VERSION ""

NS_ :

BS_:

BU_: sensors slave master

BO_ 5 SlaveConnectMaster: 1 slave
 SG_ Reset : 0|1@1+ (1,0) [0|1] "" Vector__XXX

BO_ 6 MasterConnectSlave: 1 master
 SG_ Connect_Slave : 0|1@1+ (1,0) [0|1] "" Vector__XXX

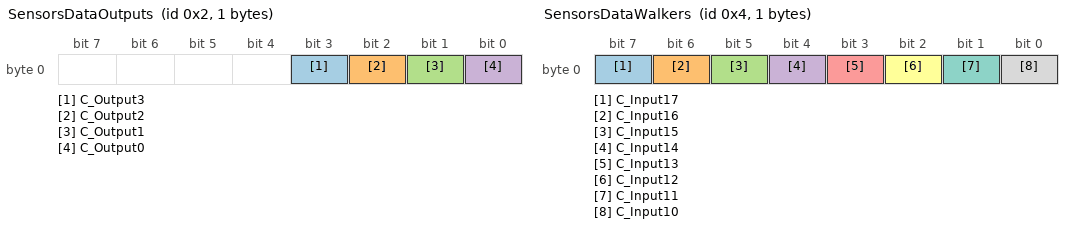
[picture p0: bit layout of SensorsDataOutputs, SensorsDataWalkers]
BO_ 2 SensorsDataOutputs: 1 sensors
 SG_ C_Output3 : 3|1@1+ (1,0) [0|1] "" Vector__XXX
 SG_ C_Output2 : 2|1@1+ (1,0) [0|1] "" Vector__XXX
 SG_ C_Output1 : 1|1@1+ (1,0) [0|1] "" Vector__XXX
 SG_ C_Output0 : 0|1@1+ (1,0) [0|1] "" Vector__XXX

BO_ 4 SensorsDataWalkers: 1 sensors
 SG_ C_Input17 : 7|1@1+ (1,0) [0|1] "" Vector__XXX
 SG_ C_Input16 : 6|1@1+ (1,0) [0|1] "" Vector__XXX
 SG_ C_Input15 : 5|1@1+ (1,0) [0|1] "" Vector__XXX
 SG_ C_Input14 : 4|1@1+ (1,0) [0|1] "" Vector__XXX
 SG_ C_Input13 : 3|1@1+ (1,0) [0|1] "" Vector__XXX
 SG_ C_Input12 : 2|1@1+ (1,0) [0|1] "" Vector__XXX
 SG_ C_Input11 : 1|1@1+ (1,0) [0|1] "" Vector__XXX
 SG_ C_Input10 : 0|1@1+ (1,0) [0|1] "" Vector__XXX

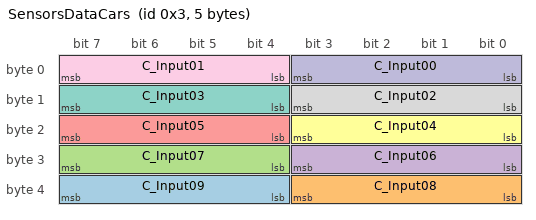
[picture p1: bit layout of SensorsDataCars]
BO_ 3 SensorsDataCars: 5 sensors
 SG_ C_Input09 : 36|4@1+ (1,0) [0|15] "" Vector__XXX
 SG_ C_Input08 : 32|4@1+ (1,0) [0|15] "" Vector__XXX
 SG_ C_Input07 : 28|4@1+ (1,0) [0|15] "" Vector__XXX
 SG_ C_Input06 : 24|4@1+ (1,0) [0|15] "" Vector__XXX
 SG_ C_Input05 : 20|4@1+ (1,0) [0|15] "" Vector__XXX
 SG_ C_Input04 : 16|4@1+ (1,0) [0|15] "" Vector__XXX
 SG_ C_Input03 : 12|4@1+ (1,0) [0|15] "" Vector__XXX
 SG_ C_Input02 : 8|4@1+ (1,0) [0|15] "" Vector__XXX
 SG_ C_Input01 : 4|4@1+ (1,0) [0|15] "" Vector__XXX
 SG_ C_Input00 : 0|4@1+ (1,0) [0|15] "" Vector__XXX

BO_ 1 RequestSensorsData: 1 master
 SG_ OK : 0|1@1+ (1,0) [0|1] "" Vector__XXX

BO_ 9 TrafficLightsControl: 7 slave
 SG_ output8_rightArrow : 49|1@1+ (1,0) [0|1] "" Vector__XXX
 SG_ output5_rightArrow : 48|1@1+ (1,0) [0|1] "" Vector__XXX
 SG_ output3_rightArrow : 47|1@1+ (1,0) [0|1] "" Vector__XXX
 SG_ output0_rightArrow : 46|1@1+ (1,0) [0|1] "" Vector__XXX
 SG_ output17_green : 45|1@1+ (1,0) [0|1] "" Vector__XXX
 SG_ output16_green : 43|1@1+ (1,0) [0|1] "" Vector__XXX
 SG_ output15_green : 41|1@1+ (1,0) [0|1] "" Vector__XXX
 SG_ output14_green : 39|1@1+ (1,0) [0|1] "" Vector__XXX
 SG_ output13_green : 37|1@1+ (1,0) [0|1] "" Vector__XXX
 SG_ output12_green : 35|1@1+ (1,0) [0|1] "" Vector__XXX
 SG_ output11_green : 33|1@1+ (1,0) [0|1] "" Vector__XXX
 SG_ output10_green : 31|1@1+ (1,0) [0|1] "" Vector__XXX
 SG_ output17_red : 44|1@1+ (1,0) [0|1] "" Vector__XXX
 SG_ output16_red : 42|1@1+ (1,0) [0|1] "" Vector__XXX
 SG_ output15_red : 40|1@1+ (1,0) [0|1] "" Vector__XXX
 SG_ output14_red : 38|1@1+ (1,0) [0|1] "" Vector__XXX
 SG_ output13_red : 36|1@1+ (1,0) [0|1] "" Vector__XXX
 SG_ output9_yellow : 29|1@1+ (1,0) [0|1] "" Vector__XXX
 SG_ output9_green : 27|1@1+ (1,0) [0|1] "" Vector__XXX
 SG_ output8_green : 24|1@1+ (1,0) [0|1] "" Vector__XXX
 SG_ output8_yellow : 26|1@1+ (1,0) [0|1] "" Vector__XXX
 SG_ output7_yellow : 23|1@1+ (1,0) [0|1] "" Vector__XXX
 SG_ output7_green : 21|1@1+ (1,0) [0|1] "" Vector__XXX
 SG_ output6_yellow : 20|1@1+ (1,0) [0|1] "" Vector__XXX
 SG_ output6_green : 18|1@1+ (1,0) [0|1] "" Vector__XXX
 SG_ output5_green : 15|1@1+ (1,0) [0|1] "" Vector__XXX
 SG_ output5_yellow : 17|1@1+ (1,0) [0|1] "" Vector__XXX
 SG_ output4_yellow : 14|1@1+ (1,0) [0|1] "" Vector__XXX
 SG_ output3_yellow : 11|1@1+ (1,0) [0|1] "" Vector__XXX
 SG_ output4_green : 12|1@1+ (1,0) [0|1] "" Vector__XXX
 SG_ output3_green : 9|1@1+ (1,0) [0|1] "" Vector__XXX
 SG_ output2_yellow : 8|1@1+ (1,0) [0|1] "" Vector__XXX
 SG_ output2_green : 6|1@1+ (1,0) [0|1] "" Vector__XXX
 SG_ output1_yellow : 5|1@1+ (1,0) [0|1] "" Vector__XXX
 SG_ output1_green : 3|1@1+ (1,0) [0|1] "" Vector__XXX
 SG_ output0_yellow : 2|1@1+ (1,0) [0|1] "" Vector__XXX
 SG_ output0_green : 0|1@1+ (1,0) [0|1] "" Vector__XXX
 SG_ output12_red : 34|1@1+ (1,0) [0|1] "" Vector__XXX
 SG_ output11_red : 32|1@1+ (1,0) [0|1] "" Vector__XXX
 SG_ output10_red : 30|1@1+ (1,0) [0|1] "" Vector__XXX
 SG_ output7_red : 22|1@1+ (1,0) [0|1] "" Vector__XXX
 SG_ output9_red : 28|1@1+ (1,0) [0|1] "" Vector__XXX
 SG_ output8_red : 25|1@1+ (1,0) [0|1] "" Vector__XXX
 SG_ output6_red : 19|1@1+ (1,0) [0|1] "" Vector__XXX
 SG_ output5_red : 16|1@1+ (1,0) [0|1] "" Vector__XXX
 SG_ output4_red : 13|1@1+ (1,0) [0|1] "" Vector__XXX
 SG_ output3_red : 10|1@1+ (1,0) [0|1] "" Vector__XXX
 SG_ output2_red : 7|1@1+ (1,0) [0|1] "" Vector__XXX
 SG_ output1_red : 4|1@1+ (1,0) [0|1] "" Vector__XXX
 SG_ output0_red : 1|1@1+ (1,0) [0|1] "" Vector__XXX

BO_ 77 CyclePhase: 8 master
 SG_ input21 : 21|1@1+ (1,0) [0|1] "" Vector__XXX
 SG_ input20 : 20|1@1+ (1,0) [0|1] "" Vector__XXX
 SG_ input19 : 19|1@1+ (1,0) [0|1] "" Vector__XXX
 SG_ input18 : 18|1@1+ (1,0) [0|1] "" Vector__XXX
 SG_ input9 : 17|1@1+ (1,0) [0|1] "" Vector__XXX
 SG_ input8 : 16|1@1+ (1,0) [0|1] "" Vector__XXX
 SG_ input7 : 15|1@1+ (1,0) [0|1] "" Vector__XXX
 SG_ input6 : 14|1@1+ (1,0) [0|1] "" Vector__XXX
 SG_ input5 : 13|1@1+ (1,0) [0|1] "" Vector__XXX
 SG_ input4 : 12|1@1+ (1,0) [0|1] "" Vector__XXX
 SG_ input3 : 11|1@1+ (1,0) [0|1] "" Vector__XXX
 SG_ input2 : 10|1@1+ (1,0) [0|1] "" Vector__XXX
 SG_ input17 : 9|1@1+ (1,0) [0|1] "" Vector__XXX
 SG_ input16 : 8|1@1+ (1,0) [0|1] "" Vector__XXX
 SG_ input15 : 7|1@1+ (1,0) [0|1] "" Vector__XXX
 SG_ input14 : 6|1@1+ (1,0) [0|1] "" Vector__XXX
 SG_ input13 : 5|1@1+ (1,0) [0|1] "" Vector__XXX
 SG_ input12 : 4|1@1+ (1,0) [0|1] "" Vector__XXX
 SG_ input11 : 3|1@1+ (1,0) [0|1] "" Vector__XXX
 SG_ input10 : 2|1@1+ (1,0) [0|1] "" Vector__XXX
 SG_ input1 : 1|1@1+ (1,0) [0|1] "" Vector__XXX
 SG_ time : 32|32@1- (1,0) [0|0] "" Vector__XXX
 SG_ input0 : 0|1@1+ (1,0) [0|1] "" Vector__XXX

EV_ T_faza4: 1 [0|0] "" 15 1 DUMMY_NODE_VECTOR3 Vector__XXX;

EV_ T_faza3: 1 [0|0] "" 15 2 DUMMY_NODE_VECTOR3 Vector__XXX;

EV_ T_faza2: 1 [0|0] "" 15 3 DUMMY_NODE_VECTOR3 Vector__XXX;

EV_ T_faza1: 1 [0|0] "" 15 4 DUMMY_NODE_VECTOR3 Vector__XXX;

EV_ Slave_On_Off: 0 [0|1] "" 1 5 DUMMY_NODE_VECTOR3 Vector__XXX;

EV_ TminP: 1 [0|0] "" 10 6 DUMMY_NODE_VECTOR3 Vector__XXX;

EV_ Master_On_Off: 0 [0|1] "" 1 7 DUMMY_NODE_VECTOR3 Vector__XXX;

EV_ Sensors_On_Off: 0 [0|1] "" 1 8 DUMMY_NODE_VECTOR3 Vector__XXX;

EV_ Tcycle: 1 [0|0] "" 60 9 DUMMY_NODE_VECTOR3 Vector__XXX;

EV_ Frequency17: 0 [0|32] "" 0 10 DUMMY_NODE_VECTOR3  sensors;

EV_ Frequency16: 0 [0|32] "" 0 11 DUMMY_NODE_VECTOR3  sensors;

EV_ Frequency15: 0 [0|32] "" 0 12 DUMMY_NODE_VECTOR3  sensors;

EV_ Frequency14: 0 [0|32] "" 0 13 DUMMY_NODE_VECTOR3  sensors;

EV_ Frequency13: 0 [0|32] "" 0 14 DUMMY_NODE_VECTOR3  sensors;

EV_ Frequency12: 0 [0|32] "" 0 15 DUMMY_NODE_VECTOR3  sensors;

EV_ Frequency11: 0 [0|32] "" 0 16 DUMMY_NODE_VECTOR3  sensors;

EV_ Frequency10: 0 [0|32] "" 0 17 DUMMY_NODE_VECTOR3  sensors;

EV_ Frequency9: 0 [0|32] "" 0 18 DUMMY_NODE_VECTOR3  sensors;

EV_ Frequency8: 0 [0|32] "" 0 19 DUMMY_NODE_VECTOR3  sensors;

EV_ Frequency7: 0 [0|32] "" 0 20 DUMMY_NODE_VECTOR3  sensors;

EV_ Frequency6: 0 [0|32] "" 0 21 DUMMY_NODE_VECTOR3  sensors;

EV_ Frequency5: 0 [0|32] "" 0 22 DUMMY_NODE_VECTOR3  sensors;

EV_ Frequency4: 0 [0|32] "" 0 23 DUMMY_NODE_VECTOR3  sensors;

EV_ Frequency3: 0 [0|32] "" 0 24 DUMMY_NODE_VECTOR3  sensors;

EV_ Frequency2: 0 [0|32] "" 0 25 DUMMY_NODE_VECTOR3  sensors;

EV_ Frequency1: 0 [0|32] "" 0 26 DUMMY_NODE_VECTOR3  sensors;

EV_ Frequency0: 0 [0|32] "" 0 27 DUMMY_NODE_VECTOR3  sensors;

EV_ Check_Input0: 0 [0|0] "" 1 28 DUMMY_NODE_VECTOR3  sensors;

EV_ Check_Input10: 0 [0|0] "" 0 29 DUMMY_NODE_VECTOR3  sensors;

EV_ Check_Input11: 0 [0|0] "" 0 30 DUMMY_NODE_VECTOR3  sensors;

EV_ Check_Input12: 0 [0|0] "" 0 31 DUMMY_NODE_VECTOR3  sensors;

EV_ Check_Input13: 0 [0|0] "" 0 32 DUMMY_NODE_VECTOR3  sensors;

EV_ Check_Input14: 0 [0|0] "" 0 33 DUMMY_NODE_VECTOR3  sensors;

EV_ Check_Input15: 0 [0|0] "" 0 34 DUMMY_NODE_VECTOR3  sensors;

EV_ Check_Input16: 0 [0|0] "" 0 35 DUMMY_NODE_VECTOR3  sensors;

EV_ Check_Input5: 0 [0|0] "" 1 36 DUMMY_NODE_VECTOR3  sensors;

EV_ Check_Input6: 0 [0|0] "" 1 37 DUMMY_NODE_VECTOR3  sensors;

EV_ Check_Input7: 0 [0|0] "" 1 38 DUMMY_NODE_VECTOR3  sensors;

EV_ Check_Input8: 0 [0|0] "" 1 39 DUMMY_NODE_VECTOR3  sensors;

EV_ Check_Input9: 0 [0|0] "" 1 40 DUMMY_NODE_VECTOR3  sensors;

EV_ Check_Input4: 0 [0|0] "" 1 41 DUMMY_NODE_VECTOR3  sensors;

EV_ Check_Input3: 0 [0|0] "" 1 42 DUMMY_NODE_VECTOR3  sensors;

EV_ Check_Input2: 0 [0|0] "" 1 43 DUMMY_NODE_VECTOR3  sensors;

EV_ Check_Input1: 0 [0|0] "" 1 44 DUMMY_NODE_VECTOR3  sensors;

EV_ Check_Input17: 0 [0|0] "" 0 45 DUMMY_NODE_VECTOR3  sensors;

EV_ Check_Output0: 0 [0|0] "" 0 46 DUMMY_NODE_VECTOR3  sensors;

EV_ Check_Output3: 0 [0|0] "" 0 47 DUMMY_NODE_VECTOR3  sensors;

EV_ Check_Output2: 0 [0|0] "" 0 48 DUMMY_NODE_VECTOR3  sensors;

EV_ Check_Output1: 0 [0|0] "" 0 49 DUMMY_NODE_VECTOR3  sensors;

EV_ Tyellow: 1 [0|0] "" 4 50 DUMMY_NODE_VECTOR3 Vector__XXX;

EV_ Tmax: 1 [0|0] "" 40 51 DUMMY_NODE_VECTOR3 Vector__XXX;

EV_ Tmin: 1 [0|0] "" 3 52 DUMMY_NODE_VECTOR3 Vector__XXX;

CM_ SG_ 77 time "Okreœla czas trwania danej fazy.";
CM_ EV_ T_faza4 "Czas œwiat³a zielone dla poszczegolnej fazy, gdy nie dzia³aj¹ sensory.";
CM_ EV_ T_faza3 "Czas œwiat³a zielone dla poszczegolnej fazy, gdy nie dzia³aj¹ sensory.";
CM_ EV_ T_faza2 "Czas œwiat³a zielone dla poszczegolnej fazy, gdy nie dzia³aj¹ sensory.";
CM_ EV_ T_faza1 "Czas œwiat³a zielone dla poszczegolnej fazy, gdy nie dzia³aj¹ sensory.";
CM_ EV_ Slave_On_Off "W³¹czenie/wy³¹czenie wêz³a 'slave
'
";
CM_ EV_ TminP "Minimalny czas œwiat³a zielonego z pieszymi.";
CM_ EV_ Master_On_Off "W³¹czenie/wy³¹czenie wêz³a 'master'
";
CM_ EV_ Sensors_On_Off "W³¹czenie/wy³¹czenie wêz³a 'sensors'
";
CM_ EV_ Tcycle "Ca³kowity czas cyklu.";
CM_ EV_ Frequency17 "Czujnik natê¿enia ruchu na wlocie";
CM_ EV_ Frequency16 "Czujnik natê¿enia ruchu na wlocie";
CM_ EV_ Frequency15 "Czujnik natê¿enia ruchu na wlocie";
CM_ EV_ Frequency14 "Czujnik natê¿enia ruchu na wlocie";
CM_ EV_ Frequency13 "Czujnik natê¿enia ruchu na wlocie";
CM_ EV_ Frequency12 "Czujnik natê¿enia ruchu na wlocie";
CM_ EV_ Frequency11 "Czujnik natê¿enia ruchu na wlocie";
CM_ EV_ Frequency10 "Czujnik natê¿enia ruchu na wlocie";
CM_ EV_ Frequency9 "Czujnik natê¿enia ruchu na wlocie";
CM_ EV_ Frequency8 "Czujnik natê¿enia ruchu na wlocie";
CM_ EV_ Frequency7 "Czujnik natê¿enia ruchu na wlocie";
CM_ EV_ Frequency6 "Czujnik natê¿enia ruchu na wlocie";
CM_ EV_ Frequency5 "Czujnik natê¿enia ruchu na wlocie";
CM_ EV_ Frequency4 "Czujnik natê¿enia ruchu na wlocie";
CM_ EV_ Frequency3 "Czujnik natê¿enia ruchu na wlocie";
CM_ EV_ Frequency2 "Czujnik natê¿enia ruchu na wlocie";
CM_ EV_ Frequency1 "Czujnik natê¿enia ruchu na wlocie";
CM_ EV_ Frequency0 "Czujnik natê¿enia ruchu na wlocie";
CM_ EV_ Check_Input0 "Czujnik obecnoœci samochodów na wlocie";
CM_ EV_ Check_Input10 "Czujnik obecnoœci pieszych na wlocie";
CM_ EV_ Check_Input11 "Czujnik obecnoœci pieszych na wlocie";
CM_ EV_ Check_Input12 "Czujnik obecnoœci pieszych na wlocie";
CM_ EV_ Check_Input13 "Czujnik obecnoœci pieszych na wlocie";
CM_ EV_ Check_Input14 "Czujnik obecnoœci pieszych na wlocie";
CM_ EV_ Check_Input15 "Czujnik obecnoœci pieszych na wlocie";
CM_ EV_ Check_Input16 "Czujnik obecnoœci pieszych na wlocie";
CM_ EV_ Check_Input5 "Czujnik obecnoœci samochodów na wlocie";
CM_ EV_ Check_Input6 "Czujnik obecnoœci samochodów na wlocie";
CM_ EV_ Check_Input7 "Czujnik obecnoœci samochodów na wlocie";
CM_ EV_ Check_Input8 "Czujnik obecnoœci samochodów na wlocie";
CM_ EV_ Check_Input9 "Czujnik obecnoœci samochodów na wlocie";
CM_ EV_ Check_Input4 "Czujnik obecnoœci samochodów na wlocie";
CM_ EV_ Check_Input3 "Czujnik obecnoœci samochodów na wlocie";
CM_ EV_ Check_Input2 "Czujnik obecnoœci samochodów na wlocie";
CM_ EV_ Check_Input1 "Czujnik obecnoœci samochodów na wlocie";
CM_ EV_ Check_Input17 "Czujnik obecnoœci pieszych na wlocie";
CM_ EV_ Check_Output0 "Blokada wylotu 0";
CM_ EV_ Check_Output3 "Blokada wylotu 3";
CM_ EV_ Check_Output2 "Blokada wylotu 2";
CM_ EV_ Check_Output1 "Blokada wylotu 1";
CM_ EV_ Tyellow "Czas œwiat³a ¿ó³tego.";
CM_ EV_ Tmax "Maksymalny czas œwiat³a zielonego.";
CM_ EV_ Tmin "Minimalny czas œwiat³a zielonego bez pieszych.";
SIG_VALTYPE_ 77 time : 1;
